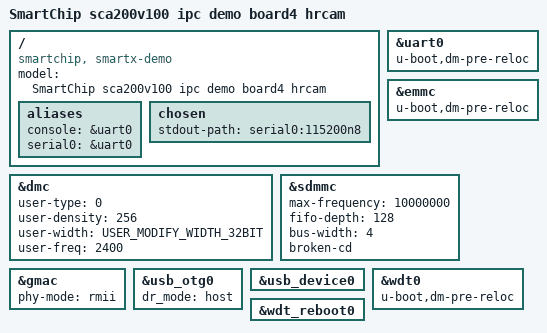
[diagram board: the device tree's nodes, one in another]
/*
 * Copyright 2015 Hans de Goede <hdegoede@redhat.com>
 *
 * Minimal dts file for the MSI Primo81 for u-boot only
 *
 * SPDX-License-Identifier:     GPL-2.0+ or X11
 */

/dts-v1/;

#include "smartchip-sca200v100.dtsi"
#include "smartchip-sca200v100-ddr4.dtsi"
#include "sca200v100_cfg_clock.dtsi"
#include "sca200v100_cfg_pin_bd4_hrcam.dtsi"
#include "sca200v100_cfg_extra.dtsi"

//#if gCONFIG_SMARTCHIP_SMARTX_DDR_TYPE==ddr3
//#include "smartchip-smartx-ddr3.dtsi"
//#elif gCONFIG_SMARTCHIP_SMARTX_DDR_TYPE==ddr4
//#include "smartchip-smartx-ddr4.dtsi"
//#elif gCONFIG_SMARTCHIP_SMARTX_DDR_TYPE==lpddr3
//#include "smartchip-smartx-lpddr3.dtsi"
//#endif

/ {
	model = "SmartChip sca200v100 ipc demo board4 hrcam";
	compatible = "smartchip, smartx-demo";

	aliases {
		console = &uart0;
		serial0 = &uart0;
	};

	chosen {
		stdout-path = "serial0:115200n8";
	};

};

&dmc {
	user-type = <0>; //0:ddr4
	user-density = <256>; // 256Mx16bit
	user-width = <USER_MODIFY_WIDTH_32BIT>; // 1:16bit; 2:32bit;
	user-freq = <2400>; // 2400M
};

&uart0 {
	u-boot,dm-pre-reloc;
	status = "okay";
};

&emmc {
	u-boot,dm-pre-reloc;
	status = "okay";
};

&sdmmc {
	max-frequency = <10000000>;
	fifo-depth = <128>;
	bus-width = <4>;
	broken-cd;
	status = "okay";
};

&gmac {
	phy-mode = "rmii";
	status = "okay";
};

&usb_otg0 {
	dr_mode = "host";
	status = "okay";
};

&usb_device0 {
	status = "okay";
};

&wdt0 {
	u-boot,dm-pre-reloc;
	status = "okay";
};

&wdt_reboot0 {
	status = "okay";
};

